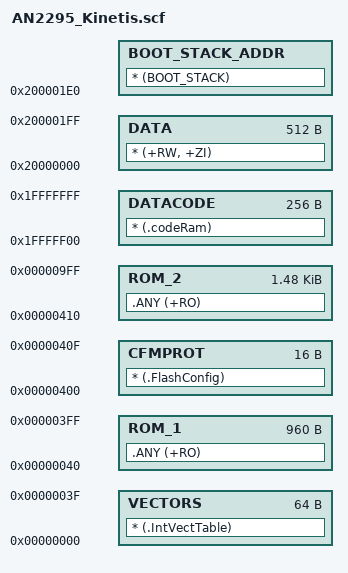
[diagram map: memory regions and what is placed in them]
#! armcc -E

#define INTFLASH_BASE_ADDR     	0x00000000
#define INTFLASH_SIZE          	0x00000a00

#define VECTORS_BASE_ADDR		0x00000000
#define VECTORS_SIZE			0x00000040

#define CFMPROT_BASE_ADDR		0x00000400
#define CFMPROT_SIZE			0x00000010

#define ROM1_BASE_ADDR			(VECTORS_BASE_ADDR + VECTORS_SIZE)
#define ROM1_SIZE				(CFMPROT_BASE_ADDR - ROM1_BASE_ADDR)

#define ROM2_BASE_ADDR			(CFMPROT_BASE_ADDR + CFMPROT_SIZE)
#define ROM2_SIZE				(INTFLASH_SIZE - ROM2_BASE_ADDR)

#define DATA_BASE_ADDR			0x20000000
#define DATA_SIZE				0x00000200

#define DATACODE_BASE_ADDR		0x1fffff00
#define DATACODE_SIZE			0x00000100

LR_VECTORS VECTORS_BASE_ADDR VECTORS_SIZE
{
    VECTORS VECTORS_BASE_ADDR VECTORS_SIZE
    {
        * (.IntVectTable)		
    }
}

LR_1 ROM1_BASE_ADDR ROM1_SIZE
{
	ROM_1 ROM1_BASE_ADDR ROM1_SIZE
    {	
		.ANY (+RO)
    }	
}

LR_CFMPROT CFMPROT_BASE_ADDR CFMPROT_SIZE
{
    CFMPROT CFMPROT_BASE_ADDR CFMPROT_SIZE
    {
        * (.FlashConfig)		
    }
}

LR_2 ROM2_BASE_ADDR ROM2_SIZE
{	
	ROM_2 ROM2_BASE_ADDR ROM2_SIZE
    {
		.ANY (+RO)
    }
}

LR_RAM DATACODE_BASE_ADDR
{
    DATA DATA_BASE_ADDR DATA_SIZE
    {
        * (+RW, +ZI)
    }
	
	DATACODE DATACODE_BASE_ADDR DATACODE_SIZE
    {
        * (.codeRam)
    }
	
    BOOT_STACK_ADDR (DATA_BASE_ADDR + DATA_SIZE - 32) ALIGN 16
    {
		* (BOOT_STACK)
    }
}
